# LKS32MC08x register map
Vendor: Linko Ltd.; Series: LKS32MC08x; File version: 1.0
CPU: CM0 r1p0, little endian, MPU, no FPU, 3 interrupt priority bits
Registers are 32-bit, read-write, reset 0x0 unless marked. A register's access mark holds for its fields unless they carry their own. Offsets are from the block's base; [hi:lo] are bit positions; 'fields as' and 'values as' point back to an identical list.

## HALL — HALL registers
Base 0x40011000
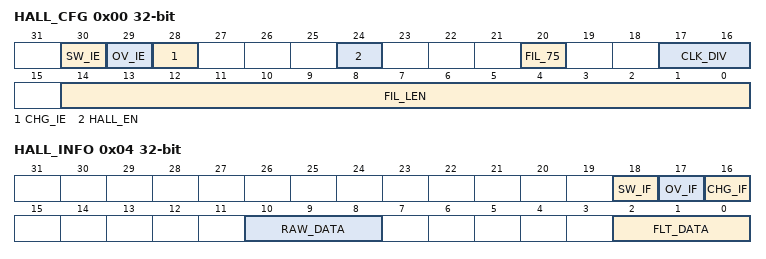
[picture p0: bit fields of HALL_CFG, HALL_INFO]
0x00 HALL_CFG — Hall Configuration Register
  [30] SW_IE — Software to trigger hall irq enable
    0=Disabled (software trigger interrupt disable); 1=Enabled (software trigger interrupt enable)
  [29] OV_IE — overflow counter interrupt enable
    0=Disabled (overflow counter interrupt disable); 1=Enabled (overflow counter interrupt enable)
  [28] CHG_IE — hall signal change interrupt enable
    0=Disabled (hall signal change interrupt disable); 1=Enabled (hall signal change interrupt enable)
  [24] HALL_EN — hall enable
    0=Disabled (hall module disable); 1=Enabled (hall module enable)
  [20] FIL_75 — hall signal first filter:7_5 filter control bit
    0=Disabled (hall signal 7_5 filter disable); 1=Enabled (hall signal 7_5 filter enable)
  [17:16] CLK_DIV — hall clock frequency divider
    0=Value (Divide 1); 1=Value (Divide 2); 2=Value (Divide 4); 3=Value (Divide 8)
  [14:0] FIL_LEN — hall signal second filter:filter length control bits. Filter length from 1 to 32768
0x04 HALL_INFO — Hall Information register
  [18] SW_IF wo — software to trigger hall irq
  [17] OV_IF — overflow counter event
    0=Value (read 0 means overflow counter event not happened, write 0 is useless); 1=Value (read 1 means overflow counter event happened, write 1 to clear)
  [16] CHG_IF — hall signal change event
    0=Value (read 0 means hall signal change event not happened, write 0 is useless); 1=Value (read 1 means hall signal change event happened, write 1 to clear)
  [10:8] RAW_DATA ro — hall signal data without filtered
  [2:0] FLT_DATA ro — hall signal data with filtered
0x08 HALL_WIDTH ro
  [23:0] CAP_CNT — hall signal change event happened,captured hall counter value by hardware
0x0C HALL_TH — Hall Threshold Register
  [23:0] TH — overflow event target value
0x10 HALL_CNT — Hall Counter Register
  [23:0] CNT — hall counter value

## TIMER0 — TIMER0 registers
Base 0x40011800
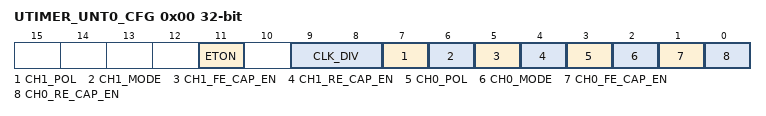
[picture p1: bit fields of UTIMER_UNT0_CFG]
0x00 UTIMER_UNT0_CFG — Timer configuration
  [11] ETON — Timer external trigger
    0=IT (Free run); 1=ET (Extrenal trigger)
  [9:8] CLK_DIV — Timer clock division ratio
  [7] CH1_POL — Channel 1 output polarity at zero-crossing in comparision mode
    0=L (Output 0); 1=H (Output 1)
  [6] CH1_MODE — Channel 1 mode
    0=CMP (Comparison mode); 1=CAP (Capture mode)
  [5] CH1_FE_CAP_EN — Channel 1 falling edge capture enable
    0=Disabled (Falling edge event disabled); 1=Enabled (Falling edge event enabled)
  [4] CH1_RE_CAP_EN — Channel 1 rising edge capture enable
    0=Disabled (Rising edge event disabled); 1=Enabled (Rising edge event enabled)
  [3] CH0_POL — Channel 0 output polarity at zero-crossing in comparision mode
    0=L (Output 0); 1=H (Output 1)
  [2] CH0_MODE — Channel 0 mode
    0=CMP (Comparison mode); 1=CAP (Capture mode)
  [1] CH0_FE_CAP_EN — Channel 0 falling edge capture enable
    values as CH1_FE_CAP_EN
  [0] CH0_RE_CAP_EN — Channel 0 rising edge capture enable
    values as CH1_RE_CAP_EN
0x04 UTIMER_UNT0_TH — Timer counter threshold, timer will count from 0 to TH, then over again
0x08 UTIMER_UNT0_CNT — Timer current counter value (write to set)
0x0C UTIMER_UNT0_CMP0 — Timer Channel0 CMP/CAP threshold
0x10 UTIMER_UNT0_CMP1 — Timer Channel1 CMP/CAP threshold
0x14 UTIMER_UNT0_EVT — Timer External Trigger Event
  [2:0] EVT_SRC — external event select
    0=MCPWM_TADC2 (Use MCPWM TADC2 as trigger); 1=MCPWM_TADC3 (Use MCPWM TADC3 as trigger); 2=T1_CH0 (Use timer1 channel 0 as trigger); 3=T1_CH1 (Use timer1 channel 1 as trigger); 4=T2_CH0 (Use timer2 channel 0 as trigger); 5=T2_CH1 (Use timer2 channel 1 as trigger); 7=T3_CH1 (Use timer3 channel 0 as trigger); 6=T3_CH0 (Use timer3 channel 1 as trigger)
